# STM32G553 register map
File version: 2.0.0
CPU: CM33 r0p4, little endian, MPU, FPU, 4 interrupt priority bits
Registers are 32-bit, read-write, reset 0x0 unless marked. A register's access mark holds for its fields unless they carry their own. Offsets are from the block's base; [hi:lo] are bit positions; {n}, {i} and the like mark numbered series.

## RNG — RNG register block
Base 0x46006800
Same registers: RNG_S 0x56006800
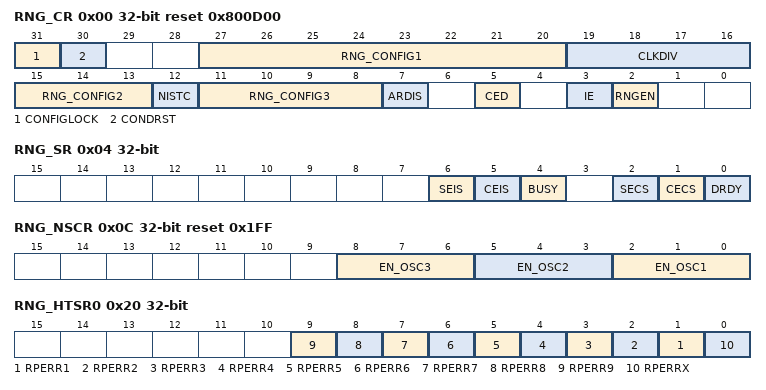
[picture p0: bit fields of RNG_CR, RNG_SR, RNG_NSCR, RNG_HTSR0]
0x00 RNG_CR reset 0x800D00 — RNG control register
  [31] CONFIGLOCK — RNG configuration lock
    0=Writes to the RNG_NSMR, RNG_NSCR, RNG_HTCR and the RNG_CR configuration bits [29:4] are allowed; 1=Writes to the RNG_NSMR, RNG_NSCR, RNG_HTCR and the RNG_CR configuration bits [29:4] are ignored until the next RNG reset
  [30] CONDRST — Conditioning soft reset
  [27:20] RNG_CONFIG1 — RNG configuration 1
  [19:16] CLKDIV — Clock divider factor
    0=internal RNG clock after divider is similar to incoming RNG clock; 1=two RNG clock cycles per internal RNG clock; 2=2less thansup>2less than/sup> (= 4) RNG clock cycles per internal RNG clock; 15=2less thansup>15less than/sup> RNG clock cycles per internal clock (for example an incoming 48MHz RNG clock becomes a 1
  [15:13] RNG_CONFIG2 — RNG configuration 2
  [12] NISTC — NIST custom
    0=Hardware default values for NIST compliant RNG; 1=Custom values for NIST compliant RNG
  [11:8] RNG_CONFIG3 — RNG configuration 3
  [7] ARDIS — Auto reset disable
    0=Auto-reset is enabled; 1=Auto-reset is disabled
  [5] CED — Clock error detection
    0=Clock error detection is enabled; 1=Clock error detection is disabled
  [3] IE — Interrupt enable
    0=RNG interrupt is disabled; 1=RNG interrupt is enabled
  [2] RNGEN — True random number generator enable
    0=True random number generator disabled; 1=True random number generator enabled
0x04 RNG_SR — RNG status register
  [6] SEIS — Seed error interrupt status
    0=No faulty sequence detected; 1=At least one faulty sequence is detected
  [5] CEIS — Clock error interrupt status
    0=The RNG clock is correct (fRNGCLK> fHCLK/32); 1=The RNG clock before the internal divider is detected too slow (fRNGCLKless than fHCLK/32)
  [4] BUSY ro
    0=Idle; 1=Busy
  [2] SECS ro — Seed error current status
    0=No faulty sequence has currently been detected; 1=At least one of the following faulty sequence has been detected:
  [1] CECS ro — Clock error current status
    0=The RNG clock is correct (fRNGCLK> fHCLK/32); 1=The RNG clock is too slow (fRNGCLKless than fHCLK/32)
  [0] DRDY ro — Data ready
    0=No valid random data ready; 1=Valid random data ready
0x08 RNG_DR ro — RNG data register
  [31:0] RNDATA — Random data
0x0C RNG_NSCR reset 0x1FF — RNG noise source control register
  [8:6] EN_OSC3 — When the RNG is enabled (RNGEN bit set), each bit of this bitfield enables one of the three inputs from the oscillator instance number 3.
  [5:3] EN_OSC2 — When the RNG is enabled (RNGEN bit set), each bit of this bitfield enables one of the three inputs from the oscillator instance number 2.
  [2:0] EN_OSC1 — When the RNG is enabled (RNGEN bit set), each bit of this bitfield enables one of the three inputs from the oscillator instance number 1.
0x10 RNG_HTCR0 reset 0x72AC — RNG health test control register 0
  [31:0] HTCFG — health test configuration
{0x10+4i} RNG_HTCR{i} reset 0x3FFFF (i=1..3) — RNG health test control register {i}
  [31:0] HTCFG — health test configuration
0x20 RNG_HTSR0 ro — RNG health test status register 0
  [n] RPERR{n} (n=1..9) — Repetitive error for oscillator i
    0=No repetitive test error found in oscillator i; 1=Repetitive test error found in oscillator i
  [0] RPERRX — Repetitive error after the XOR
    0=No repetitive test error found after the XOR clock tree; 1=Repetitive test error found after the XOR clock tree
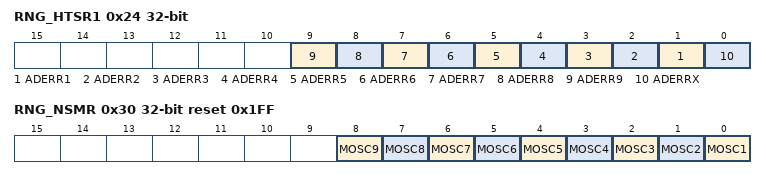
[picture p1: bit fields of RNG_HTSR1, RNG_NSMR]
0x24 RNG_HTSR1 ro — RNG health test status register 1
  [n] ADERR{n} (n=1..9) — Adaptative error for oscillator i
    0=No adaptative test error found in oscillator i; 1=Adaptative test error found in oscillator i
  [0] ADERRX — Adaptative error after the XOR
    0=No adaptative test error found after the XOR clock tree; 1=Adaptative test error found after the XOR clock tree
0x30 RNG_NSMR reset 0x1FF — RNG noise source mask register
  [all] fields
    0=Oscillator i is masked, and related health tests are deactivated; 1=Oscillator i is not masked
  [n-1] MOSC{n} (n=1..9) — Mask oscillator i
